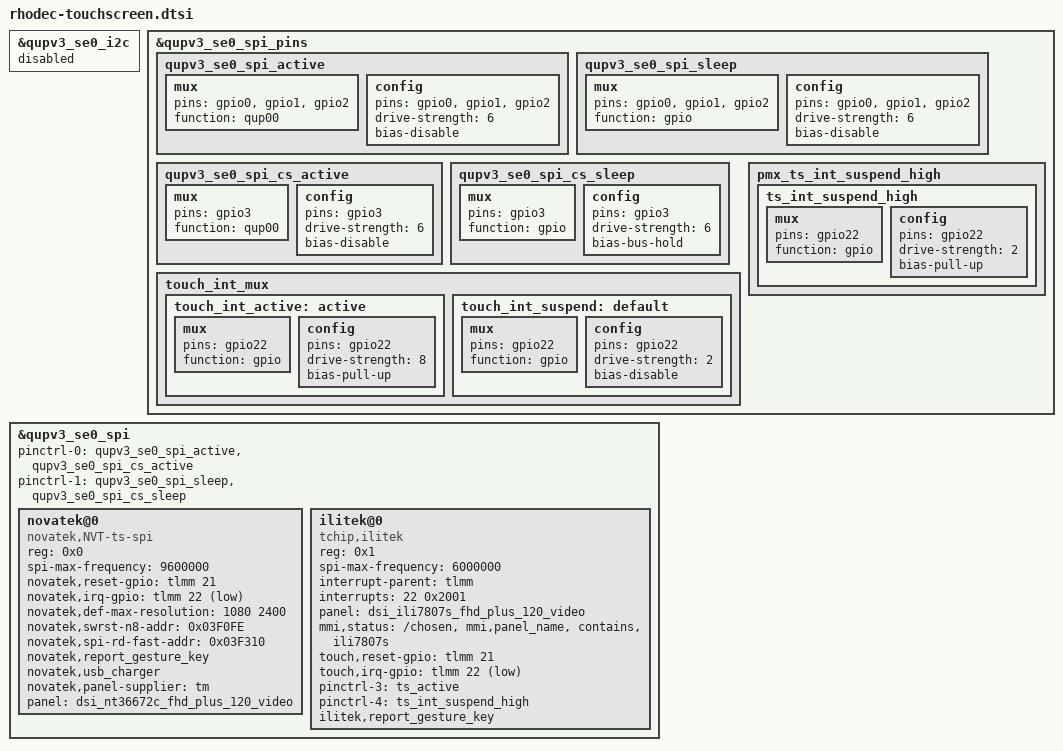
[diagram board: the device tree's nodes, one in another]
/*
 * Copyright (c) 2019, The Linux Foundation. All rights reserved.
 *
 * This program is free software; you can redistribute it and/or modify
 * it under the terms of the GNU General Public License version 2 and
 * only version 2 as published by the Free Software Foundation.
 *
 * This program is distributed in the hope that it will be useful,
 * but WITHOUT ANY WARRANTY; without even the implied warranty of
 * MERCHANTABILITY or FITNESS FOR A PARTICULAR PURPOSE.  See the
 * GNU General Public License for more details.
 */

&qupv3_se0_i2c {
	status = "disabled";
};

&qupv3_se0_spi_pins {
	qupv3_se0_spi_active: qupv3_se0_spi_active {
		mux {
			pins = "gpio0", "gpio1", "gpio2";
			function = "qup00";
		};

		config {
			pins = "gpio0", "gpio1", "gpio2";
			drive-strength = <6>;
			bias-disable;
		};
	};

	qupv3_se0_spi_sleep: qupv3_se0_spi_sleep {
		mux {
			pins = "gpio0", "gpio1", "gpio2";
			function = "gpio";
		};

		config {
			pins = "gpio0", "gpio1", "gpio2";
			drive-strength = <6>;
			bias-disable;
		};
	};

	qupv3_se0_spi_cs_active: qupv3_se0_spi_cs_active {
		mux {
			pins = "gpio3";
			function = "qup00";
		};

		config {
			pins = "gpio3";
			drive-strength = <6>;
			bias-disable;
		};
	};

	qupv3_se0_spi_cs_sleep: qupv3_se0_spi_cs_sleep {
		mux {
			pins = "gpio3";
			function = "gpio";
		};

		config {
			pins = "gpio3";
			drive-strength = <6>;
			bias-bus-hold;
		};
	};
	touch_int_mux {
		touch_int_active: active {
			mux {
				pins = "gpio22";
				function = "gpio";
			};
			config {
				pins = "gpio22";
				drive-strength = <8>;
				bias-pull-up;
			};
		};

		touch_int_suspend: default {
			mux {
				pins = "gpio22";
				function = "gpio";
			};
			config {
				pins = "gpio22";
				drive-strength = <2>;
				bias-disable;
			};
		};
	};

	pmx_ts_int_suspend_high {
		ts_int_suspend_high: ts_int_suspend_high {
			mux {
				pins = "gpio22";
				function = "gpio";
			};
			config {
				pins = "gpio22";
				drive-strength = <2>;
				bias-pull-up;
			};
		};
	};
};

&qupv3_se0_spi {
	status = "ok";
	pinctrl-0 = <&qupv3_se0_spi_active &qupv3_se0_spi_cs_active>;
	pinctrl-1 = <&qupv3_se0_spi_sleep &qupv3_se0_spi_cs_sleep>;
	novatek@0{
		compatible = "novatek,NVT-ts-spi";
		reg = <0x0>;
		spi-max-frequency = <9600000>;  /* 4800000,9600000,15000000,19200000 */
		novatek,reset-gpio = <&tlmm 21 0x00>;
		novatek,irq-gpio = <&tlmm 22 0x2001>;
		novatek,def-max-resolution = <1080 2400>;
		novatek,swrst-n8-addr = <0x03F0FE>;
		novatek,spi-rd-fast-addr = <0x03F310>;
		novatek,report_gesture_key;
		novatek,usb_charger;
		novatek,panel-supplier = "tm";
		panel = <&dsi_nt36672c_fhd_plus_120_video>;
		status = "ok";
	};
	ilitek@0 {
		compatible = "tchip,ilitek";
		reg = <0x1>;
		spi-max-frequency = <6000000>;
		interrupt-parent = <&tlmm>;
		interrupts = <22 0x2001>;
		panel = <&dsi_ili7807s_fhd_plus_120_video>;
		mmi,status = "/chosen","mmi,panel_name","contains","ili7807s";
		touch,reset-gpio = <&tlmm 21 0x00>;
		touch,irq-gpio = <&tlmm 22 0x2001>;
		pinctrl-names = "pmx_ts_int_active","pmx_ts_int_suspend_high";
		pinctrl-3 = <&ts_active>;
		pinctrl-4 = <&ts_int_suspend_high>;
		ilitek,report_gesture_key;
		status = "ok";
	};
};
